VERSION ""

NS_ :

BS_:

BU_: PC_SG BMS FC TMS CANmod FC

VAL_TABLE_ gov_e_sts 7 "motor_run_error" 6 "hv_run_error" 5 "driver_interface_error" 4 "motor_startup_error" 3 "hv_startup_error" 2 "gov_running" 1 "gov_startup" 0 "gov_init" ;

BO_ 255 VC_Status: 8 PC_SG
 SG_ VC_govStatus : 7|8@0+ (1,0) [0|255] ""  FC

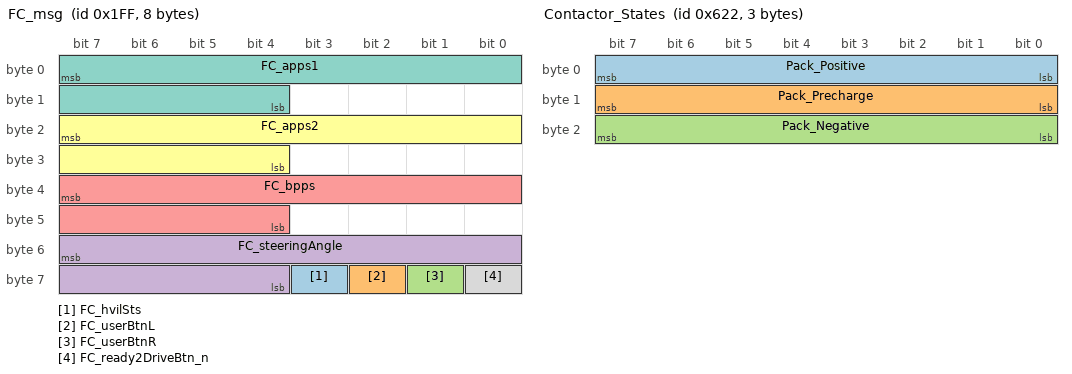
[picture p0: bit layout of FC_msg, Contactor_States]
BO_ 511 FC_msg: 8 FC
 SG_ FC_hvilSts : 59|1@0+ (1,0) [0|1] ""  PC_SG
 SG_ FC_userBtnL : 58|1@0+ (1,0) [0|1] ""  PC_SG
 SG_ FC_userBtnR : 57|1@0+ (1,0) [0|1] ""  PC_SG
 SG_ FC_steeringAngle : 55|12@0+ (1,0) [0|4095] ""  PC_SG
 SG_ FC_bpps : 39|12@0+ (1,0) [0|4095] ""  PC_SG
 SG_ FC_apps2 : 23|12@0+ (1,0) [0|4095] ""  PC_SG
 SG_ FC_apps1 : 7|12@0+ (1,0) [0|4095] ""  PC_SG
 SG_ FC_ready2DriveBtn_n : 56|1@0+ (1,0) [0|1] ""  PC_SG

BO_ 256 FC_cmd: 8 PC_SG
 SG_ FC_ready2DriveSpkr : 0|1@0+ (1,0) [0|1] ""  FC
 SG_ FC_brakeLight : 1|1@0+ (1,0) [0|1] ""  FC

BO_ 1570 Contactor_States: 3 FC
 SG_ Pack_Positive : 0|8@1+ (1,0) [0|0] ""  BMS
 SG_ Pack_Precharge : 8|8@1+ (1,0) [0|0] ""  BMS
 SG_ Pack_Negative : 16|8@1+ (1,0) [0|0] ""  BMS

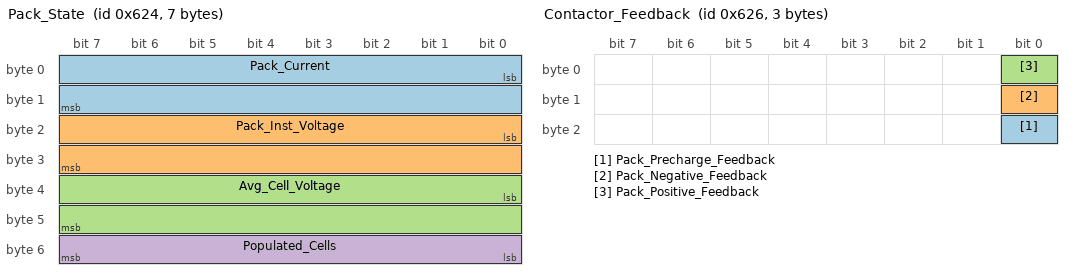
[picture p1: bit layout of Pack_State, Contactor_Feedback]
BO_ 1572 Pack_State: 7 BMS
 SG_ Pack_Current : 0|16@1+ (0.1,0) [0|0] "Amps"  FC
 SG_ Pack_Inst_Voltage : 16|16@1+ (0.1,0) [0|0] "Volts"  FC
 SG_ Avg_Cell_Voltage : 32|16@1+ (0.0001,0) [0|0] "Volts"  FC
 SG_ Populated_Cells : 48|8@1+ (1,0) [0|0] "Num"  FC

BO_ 1571 Pack_Current_Limits: 4 BMS
 SG_ Pack_CCL : 0|16@1+ (1,0) [0|0] "Amps"  FC
 SG_ Pack_DCL : 16|16@1+ (1,0) [0|0] "Amps"  FC

BO_ 1573 Pack_SOC: 3 BMS
 SG_ Pack_SOC : 0|8@1+ (0.5,0) [0|0] "Percent"  FC
 SG_ Maximum_Pack_Voltage : 8|16@1+ (0.1,0) [0|0] "Volts"  FC

BO_ 1574 Contactor_Feedback: 3 BMS
 SG_ Pack_Precharge_Feedback : 16|1@1+ (1,0) [0|1] ""  FC
 SG_ Pack_Negative_Feedback : 8|1@1+ (1,0) [0|1] ""  FC
 SG_ Pack_Positive_Feedback : 0|1@1+ (1,0) [0|1] ""  FC

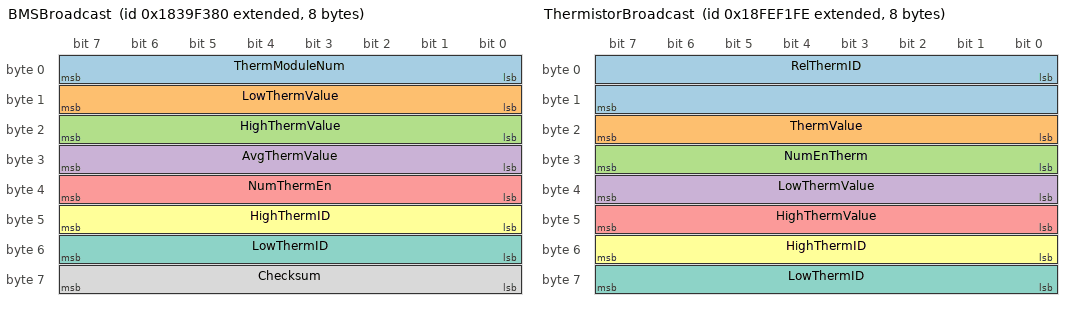
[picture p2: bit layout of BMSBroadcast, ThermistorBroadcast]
BO_ 2553934720 BMSBroadcast: 8 TMS
 SG_ ThermModuleNum : 0|8@1+ (1,0) [0|0] "" BMS
 SG_ LowThermValue : 8|8@1- (1,0) [0|0] " C" BMS
 SG_ HighThermValue : 16|8@1- (1,0) [0|0] " C" BMS
 SG_ AvgThermValue : 24|8@1- (1,0) [0|0] " C" BMS
 SG_ NumThermEn : 32|8@1+ (1,0) [0|0] "" BMS
 SG_ HighThermID : 40|8@1+ (1,0) [0|0] "" BMS
 SG_ LowThermID : 48|8@1+ (1,0) [0|0] "" BMS
 SG_ Checksum : 56|8@1- (1,0) [0|0] "" BMS

BO_ 2566844926 ThermistorBroadcast: 8 TMS
 SG_ RelThermID : 0|16@1+ (1,0) [0|0] ""  BMS
 SG_ ThermValue : 16|8@1- (1,0) [0|0] " C"  BMS
 SG_ NumEnTherm : 24|8@1- (1,0) [0|0] ""  BMS
 SG_ LowThermValue : 32|8@1- (1,0) [0|0] " C"  BMS
 SG_ HighThermValue : 40|8@1- (1,0) [0|0] " C"  BMS
 SG_ HighThermID : 48|8@1+ (1,0) [0|0] ""  BMS
 SG_ LowThermID : 56|8@1+ (1,0) [0|0] ""  BMS

BO_ 1 GnssStatus: 1 CANmod
 SG_ FixType : 0|3@1+ (1,0) [0|5] ""  FC
 SG_ Satellites : 3|5@1+ (1,0) [0|31] ""  FC

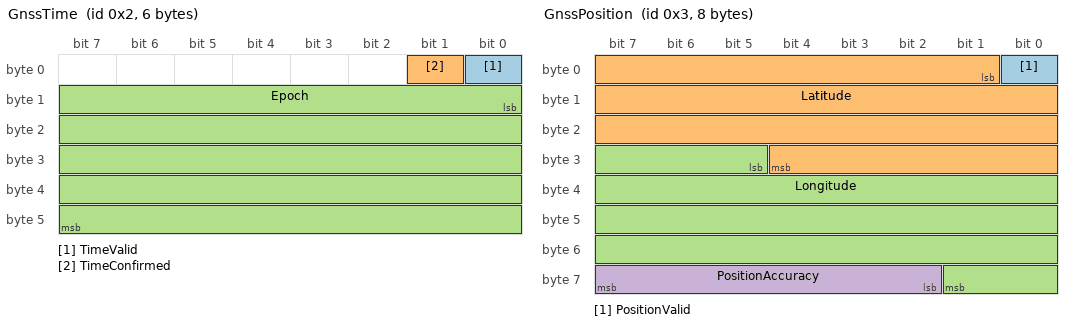
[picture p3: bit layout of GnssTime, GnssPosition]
BO_ 2 GnssTime: 6 CANmod
 SG_ TimeValid : 0|1@1+ (1,0) [0|1] ""  FC
 SG_ TimeConfirmed : 1|1@1+ (1,0) [0|1] ""  FC
 SG_ Epoch : 8|40@1+ (0.001,1577840400) [0|0] "sec"  FC

BO_ 3 GnssPosition: 8 CANmod
 SG_ PositionValid : 0|1@1+ (1,0) [0|1] ""  FC
 SG_ Latitude : 1|28@1+ (1e-06,-90) [4294967206|90] "deg"  FC
 SG_ Longitude : 29|29@1+ (1e-06,-180) [4294967116|180] "deg"  FC
 SG_ PositionAccuracy : 58|6@1+ (1,0) [0|63] "m"  FC

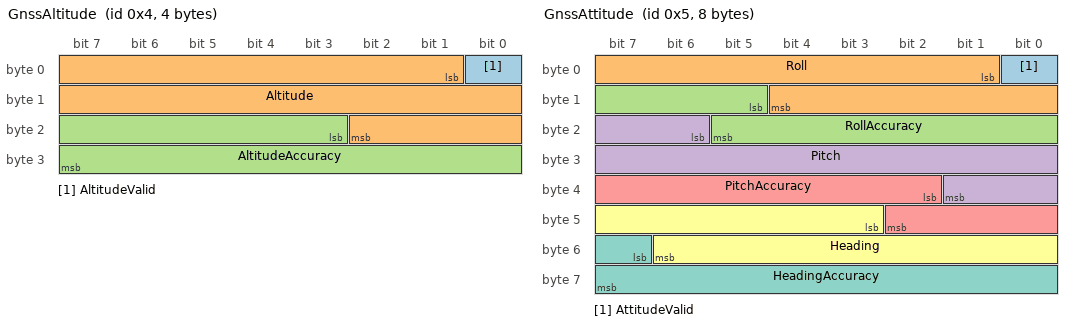
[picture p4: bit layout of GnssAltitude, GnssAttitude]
BO_ 4 GnssAltitude: 4 CANmod
 SG_ AltitudeValid : 0|1@1+ (1,0) [0|1] ""  FC
 SG_ Altitude : 1|18@1+ (0.1,-6000) [4294961296|20000] "m"  FC
 SG_ AltitudeAccuracy : 19|13@1+ (1,0) [0|8000] "m"  FC

BO_ 5 GnssAttitude: 8 CANmod
 SG_ AttitudeValid : 0|1@1+ (1,0) [0|1] ""  FC
 SG_ Roll : 1|12@1+ (0.1,-180) [4294967116|180] "deg"  FC
 SG_ RollAccuracy : 13|9@1+ (0.1,0) [0|50] "deg"  FC
 SG_ Pitch : 22|12@1+ (0.1,-90) [4294967206|90] "deg"  FC
 SG_ PitchAccuracy : 34|9@1+ (0.1,0) [0|50] "deg"  FC
 SG_ Heading : 43|12@1+ (0.1,0) [0|360] "deg"  FC
 SG_ HeadingAccuracy : 55|9@1+ (0.1,0) [0|50] "deg"  FC

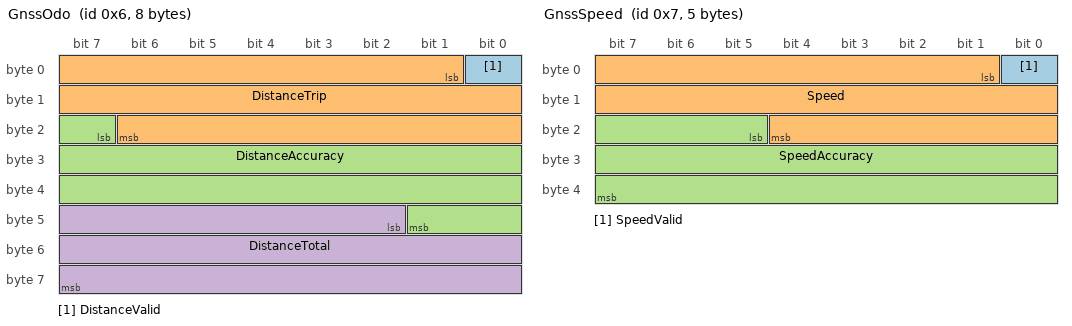
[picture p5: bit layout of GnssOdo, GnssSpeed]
BO_ 6 GnssOdo: 8 CANmod
 SG_ DistanceValid : 0|1@1+ (1,0) [0|1] ""  FC
 SG_ DistanceTrip : 1|22@1+ (1,0) [0|4194303] "m"  FC
 SG_ DistanceAccuracy : 23|19@1+ (1,0) [0|524287] "m"  FC
 SG_ DistanceTotal : 42|22@1+ (1,0) [0|4194303] "km"  FC

BO_ 7 GnssSpeed: 5 CANmod
 SG_ SpeedValid : 0|1@1+ (1,0) [0|1] ""  FC
 SG_ Speed : 1|20@1+ (0.001,0) [0|1048.575] "m/s"  FC
 SG_ SpeedAccuracy : 21|19@1+ (0.001,0) [0|524.287] "m/s"  FC

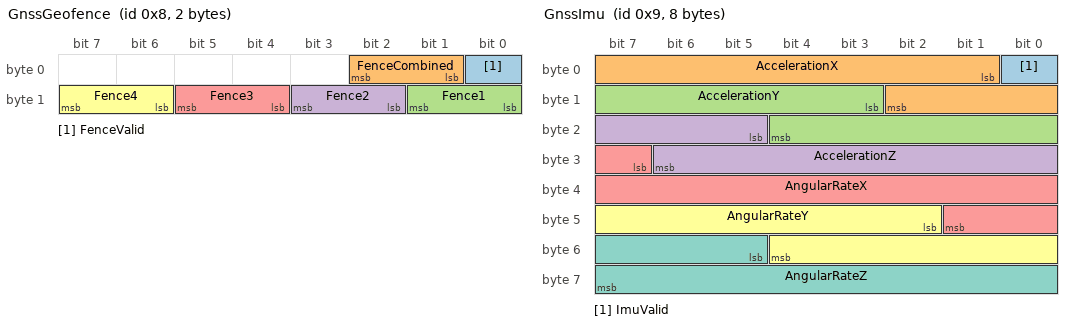
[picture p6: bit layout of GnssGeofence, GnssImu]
BO_ 8 GnssGeofence: 2 CANmod
 SG_ FenceValid : 0|1@1+ (1,0) [0|1] ""  FC
 SG_ FenceCombined : 1|2@1+ (1,0) [0|1] ""  FC
 SG_ Fence1 : 8|2@1+ (1,0) [0|1] ""  FC
 SG_ Fence2 : 10|2@1+ (1,0) [0|1] ""  FC
 SG_ Fence3 : 12|2@1+ (1,0) [0|1] ""  FC
 SG_ Fence4 : 14|2@1+ (1,0) [0|1] ""  FC

BO_ 9 GnssImu: 8 CANmod
 SG_ ImuValid : 0|1@1+ (1,0) [0|1] ""  FC
 SG_ AccelerationX : 1|10@1+ (0.125,-64) [4294967232|63.875] "m/s^2"  FC
 SG_ AccelerationY : 11|10@1+ (0.125,-64) [4294967232|63.875] "m/s^2"  FC
 SG_ AccelerationZ : 21|10@1+ (0.125,-64) [4294967232|63.875] "m/s^2"  FC
 SG_ AngularRateX : 31|11@1+ (0.25,-256) [4294967040|255.75] "deg/s"  FC
 SG_ AngularRateY : 42|11@1+ (0.25,-256) [4294967040|255.75] "deg/s"  FC
 SG_ AngularRateZ : 53|11@1+ (0.25,-256) [4294967040|255.75] "deg/s"  FC

CM_ BO_ 1572 "This ID Transmits at 8 ms.";
CM_ BO_ 1571 "This ID Transmits at 8 ms.";
CM_ BO_ 1573 "This ID Transmits at 8 ms.";
CM_ BO_ 1574 "This ID Transmits at 8 ms.";
CM_ BO_ 2553934720 "Thermistor Module - BMS Broadcast";
CM_ SG_ 2553934720 ThermModuleNum "Thermistor Module Number";
CM_ BO_ 2566844926 "Thermistor General Broadcast";
CM_ SG_ 2566844926 RelThermID "Thermistor ID relative to all configured Thermistor Modules";
CM_ BO_ 1 "GNSS information";
CM_ SG_ 1 FixType "Fix type";
CM_ SG_ 1 Satellites "Number of satellites used";
CM_ BO_ 2 "GNSS time";
CM_ SG_ 2 TimeValid "Time validity";
CM_ SG_ 2 TimeConfirmed "Time confirmed";
CM_ SG_ 2 Epoch "Epoch time";
CM_ BO_ 3 "GNSS position";
CM_ SG_ 3 PositionValid "Position validity";
CM_ SG_ 3 Latitude "Latitude";
CM_ SG_ 3 Longitude "Longitude";
CM_ SG_ 3 PositionAccuracy "Accuracy of position";
CM_ BO_ 4 "GNSS altitude";
CM_ SG_ 4 AltitudeValid "Altitude validity";
CM_ SG_ 4 Altitude "Altitude";
CM_ SG_ 4 AltitudeAccuracy "Accuracy of altitude";
CM_ BO_ 5 "GNSS attitude";
CM_ SG_ 5 AttitudeValid "Attitude validity";
CM_ SG_ 5 Roll "Vehicle roll";
CM_ SG_ 5 RollAccuracy "Vehicle roll accuracy";
CM_ SG_ 5 Pitch "Vehicle pitch";
CM_ SG_ 5 PitchAccuracy "Vehicle pitch accuracy";
CM_ SG_ 5 Heading "Vehicle heading";
CM_ SG_ 5 HeadingAccuracy "Vehicle heading accuracy";
CM_ BO_ 6 "GNSS odometer";
CM_ SG_ 6 DistanceTrip "Distance traveled since last reset";
CM_ SG_ 6 DistanceAccuracy "Distance accuracy (1-sigma)";
CM_ SG_ 6 DistanceTotal "Distance traveled in total";
CM_ BO_ 7 "GNSS speed";
CM_ SG_ 7 SpeedValid "Speed valid";
CM_ SG_ 7 Speed "Speed m/s";
CM_ SG_ 7 SpeedAccuracy "Speed accuracy";
CM_ BO_ 8 "GNSS geofence(s)";
CM_ SG_ 8 FenceValid "Geofencing status";
CM_ SG_ 8 FenceCombined "Combined (logical OR) state of all geofences";
CM_ SG_ 8 Fence1 "Geofence 1 state";
CM_ SG_ 8 Fence2 "Geofence 2 state";
CM_ SG_ 8 Fence3 "Geofence 3 state";
CM_ SG_ 8 Fence4 "Geofence 4 state";
CM_ BO_ 9 "GNSS IMU";
CM_ SG_ 9 AccelerationX "X acceleration with a resolution of 0.125 m/s^2";
CM_ SG_ 9 AccelerationY "Y acceleration with a resolution of 0.125 m/s^2";
CM_ SG_ 9 AccelerationZ "Z acceleration with a resolution of 0.125 m/s^2";
CM_ SG_ 9 AngularRateX "X angular rate with a resolution of 0.25 deg/s";
CM_ SG_ 9 AngularRateY "Y angular rate with a resolution of 0.25 deg/s";
CM_ SG_ 9 AngularRateZ "Z angular rate with a resolution of 0.25 deg/s";
BA_DEF_  "BusType" STRING ;
BA_DEF_DEF_  "BusType" "CAN";
VAL_ 255 VC_govStatus 7 "motor_run_error" 6 "hv_run_error" 5 "driver_interface_error" 4 "motor_startup_error" 3 "hv_startup_error" 2 "gov_running" 1 "gov_startup" 0 "gov_init" ;
